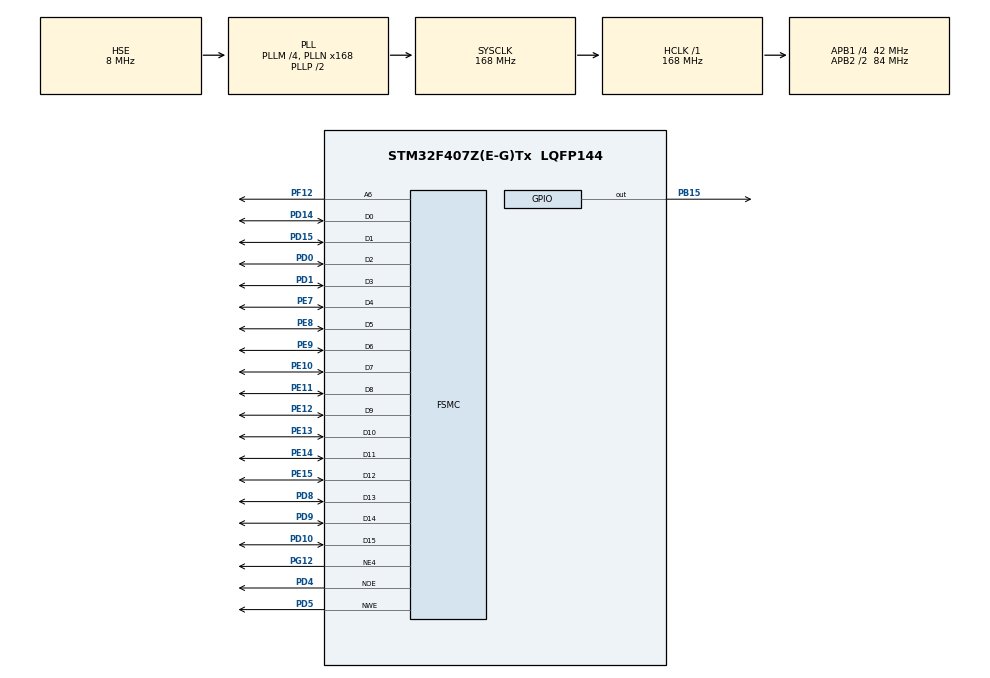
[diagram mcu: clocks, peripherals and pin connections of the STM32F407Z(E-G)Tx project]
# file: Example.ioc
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FSMC.AddressSetupTime1=2
FSMC.BusTurnAroundDuration1=2
FSMC.DataSetupTime1=16
Mcu.Family=STM32F4
Mcu.Name=STM32F407Z(E-G)Tx
Mcu.Package=LQFP144
NVIC.PriorityGroup=NVIC_PRIORITYGROUP_4
PA13.Mode=JTAG_5_pins
PA13.Signal=SYS_JTMS-SWDIO
PA14.Mode=JTAG_5_pins
PA14.Signal=SYS_JTCK-SWCLK
PA15.Mode=JTAG_5_pins
PA15.Signal=SYS_JTDI
PB15.Signal=GPIO_Output
PB3.Mode=JTAG_5_pins
PB3.Signal=SYS_JTDO-SWO
PB4.Mode=JTAG_5_pins
PB4.Signal=SYS_JTRST
PC14-OSC32_IN.Mode=LSE-External-Oscillator
PC14-OSC32_IN.Signal=RCC_OSC32_IN
PC15-OSC32_OUT.Mode=LSE-External-Oscillator
PC15-OSC32_OUT.Signal=RCC_OSC32_OUT
PD0.Signal=FSMC_D2_DA2
PD1.Signal=FSMC_D3_DA3
PD10.Signal=FSMC_D15_DA15
PD14.Signal=FSMC_D0_DA0
PD15.Signal=FSMC_D1_DA1
PD4.Signal=FSMC_NOE
PD5.Signal=FSMC_NWE
PD8.Signal=FSMC_D13_DA13
PD9.Signal=FSMC_D14_DA14
PE10.Signal=FSMC_D7_DA7
PE11.Signal=FSMC_D8_DA8
PE12.Signal=FSMC_D9_DA9
PE13.Signal=FSMC_D10_DA10
PE14.Signal=FSMC_D11_DA11
PE15.Signal=FSMC_D12_DA12
PE7.Signal=FSMC_D4_DA4
PE8.Signal=FSMC_D5_DA5
PE9.Signal=FSMC_D6_DA6
PF12.Signal=FSMC_A6
PG12.Mode=NorPsramChipSelect4_1
PG12.Signal=FSMC_NE4
PH0-OSC_IN.Mode=HSE-External-Oscillator
PH0-OSC_IN.Signal=RCC_OSC_IN
PH1-OSC_OUT.Mode=HSE-External-Oscillator
PH1-OSC_OUT.Signal=RCC_OSC_OUT
ProjectManager.HeapSize=0x200
ProjectManager.StackSize=0x400
ProjectManager.TargetToolchain=Makefile
RCC.48MHZClocksFreq_Value=84000000
RCC.AHBFreq_Value=168000000
RCC.APB1CLKDivider=RCC_HCLK_DIV4
RCC.APB1Freq_Value=42000000
RCC.APB1TimFreq_Value=84000000
RCC.APB2CLKDivider=RCC_HCLK_DIV2
RCC.APB2Freq_Value=84000000
RCC.APB2TimFreq_Value=168000000
RCC.CortexFreq_Value=168000000
RCC.EnbaleCSS=true
RCC.HCLKFreq_Value=168000000
RCC.HSE_VALUE=8000000
RCC.HSI_VALUE=16000000
RCC.PLLM=4
RCC.PLLN=168
RCC.PLLSourceVirtual=RCC_PLLSOURCE_HSE
RCC.SYSCLKFreq_VALUE=168000000
RCC.SYSCLKSource=RCC_SYSCLKSOURCE_PLLCLK
RCC.VCOOutputFreq_Value=336000000
SH.FSMC_A6.0=FSMC_A6,A6_1
SH.FSMC_D0_DA0.0=FSMC_D0,16b-d1
SH.FSMC_D10_DA10.0=FSMC_D10,16b-d1
SH.FSMC_D11_DA11.0=FSMC_D11,16b-d1
SH.FSMC_D12_DA12.0=FSMC_D12,16b-d1
SH.FSMC_D13_DA13.0=FSMC_D13,16b-d1
SH.FSMC_D14_DA14.0=FSMC_D14,16b-d1
SH.FSMC_D15_DA15.0=FSMC_D15,16b-d1
SH.FSMC_D1_DA1.0=FSMC_D1,16b-d1
SH.FSMC_D2_DA2.0=FSMC_D2,16b-d1
SH.FSMC_D3_DA3.0=FSMC_D3,16b-d1
SH.FSMC_D4_DA4.0=FSMC_D4,16b-d1
SH.FSMC_D5_DA5.0=FSMC_D5,16b-d1
SH.FSMC_D6_DA6.0=FSMC_D6,16b-d1
SH.FSMC_D7_DA7.0=FSMC_D7,16b-d1
SH.FSMC_D8_DA8.0=FSMC_D8,16b-d1
SH.FSMC_D9_DA9.0=FSMC_D9,16b-d1
SH.FSMC_NOE.0=FSMC_NOE,Lcd1
SH.FSMC_NWE.0=FSMC_NWE,Lcd1
board=custom

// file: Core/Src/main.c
/* USER CODE BEGIN Header */
/**
  ******************************************************************************
  * @file           : main.c
  * @brief          : Main program body
  ******************************************************************************
  * @attention
  *
  * Copyright (c) 2023 STMicroelectronics.
  * All rights reserved.
  *
  * This software is licensed under terms that can be found in the LICENSE file
  * in the root directory of this software component.
  * If no LICENSE file comes with this software, it is provided AS-IS.
  *
  ******************************************************************************
  */
/* USER CODE END Header */
#include "main.h"
#include "gpio.h"
#include "fsmc.h"

/* USER CODE BEGIN Includes */
#include <ILI9341.h>
/* USER CODE END Includes */

void SystemClock_Config(void);

int main(void)
{

  /* MCU Configuration--------------------------------------------------------*/

  /* Reset of all peripherals, Initializes the Flash interface and the Systick. */
  HAL_Init();

  /* Configure the system clock */
  SystemClock_Config();

  /* Initialize all configured peripherals */
  MX_GPIO_Init();
  MX_FSMC_Init();

  /* Infinite loop */
  /* USER CODE BEGIN WHILE */
  while (1)
  {
#if ILI9341_DRIVER_LIBRARY_ENABLE_TEST
  ILI9341TestFunction();
#endif
    /* USER CODE END WHILE */

  }
}

void SystemClock_Config(void)
{
  RCC_OscInitTypeDef RCC_OscInitStruct = {0};
  RCC_ClkInitTypeDef RCC_ClkInitStruct = {0};

  /** Configure the main internal regulator output voltage
  */
  __HAL_RCC_PWR_CLK_ENABLE();
  __HAL_PWR_VOLTAGESCALING_CONFIG(PWR_REGULATOR_VOLTAGE_SCALE1);

  /** Initializes the RCC Oscillators according to the specified parameters
  * in the RCC_OscInitTypeDef structure.
  */
  RCC_OscInitStruct.OscillatorType = RCC_OSCILLATORTYPE_HSE;
  RCC_OscInitStruct.HSEState = RCC_HSE_ON;
  RCC_OscInitStruct.PLL.PLLState = RCC_PLL_ON;
  RCC_OscInitStruct.PLL.PLLSource = RCC_PLLSOURCE_HSE;
  RCC_OscInitStruct.PLL.PLLM = 4;
  RCC_OscInitStruct.PLL.PLLN = 168;
  RCC_OscInitStruct.PLL.PLLP = RCC_PLLP_DIV2;
  RCC_OscInitStruct.PLL.PLLQ = 4;
  if (HAL_RCC_OscConfig(&RCC_OscInitStruct) != HAL_OK)
  {
    Error_Handler();
  }

  /** Initializes the CPU, AHB and APB buses clocks
  */
  RCC_ClkInitStruct.ClockType = RCC_CLOCKTYPE_HCLK|RCC_CLOCKTYPE_SYSCLK
                              |RCC_CLOCKTYPE_PCLK1|RCC_CLOCKTYPE_PCLK2;
  RCC_ClkInitStruct.SYSCLKSource = RCC_SYSCLKSOURCE_PLLCLK;
  RCC_ClkInitStruct.AHBCLKDivider = RCC_SYSCLK_DIV1;
  RCC_ClkInitStruct.APB1CLKDivider = RCC_HCLK_DIV4;
  RCC_ClkInitStruct.APB2CLKDivider = RCC_HCLK_DIV2;

  if (HAL_RCC_ClockConfig(&RCC_ClkInitStruct, FLASH_LATENCY_5) != HAL_OK)
  {
    Error_Handler();
  }

  /** Enables the Clock Security System
  */
  HAL_RCC_EnableCSS();
}

void Error_Handler(void)
{
  __disable_irq();
  while (1)
  {
  }
}
